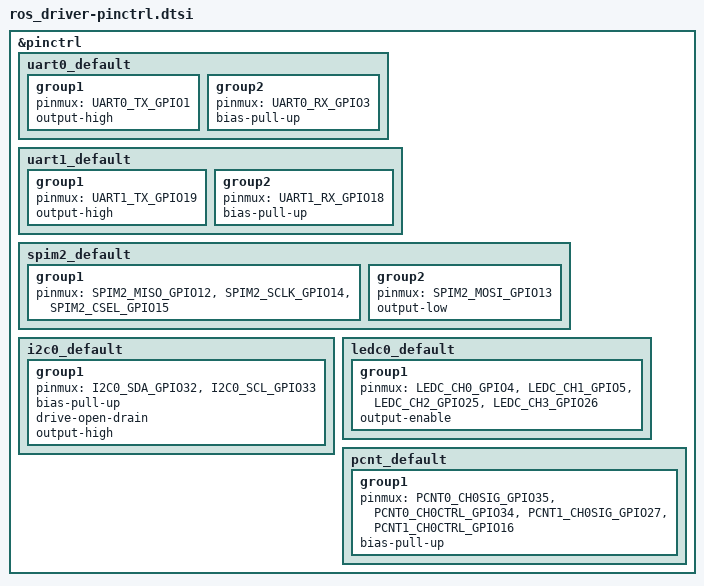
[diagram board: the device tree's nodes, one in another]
#include <zephyr/dt-bindings/pinctrl/esp-pinctrl-common.h>
#include <dt-bindings/pinctrl/esp32-pinctrl.h>
#include <zephyr/dt-bindings/pinctrl/esp32-gpio-sigmap.h>

&pinctrl {

	uart0_default: uart0_default {
		group1 {
			pinmux = <UART0_TX_GPIO1>;
			output-high;
		};
		group2 {
			pinmux = <UART0_RX_GPIO3>;
			bias-pull-up;
		};
	};

	uart1_default: uart1_default {
		group1 {
			pinmux = <UART1_TX_GPIO19>;
			output-high;
		};
		group2 {
			pinmux = <UART1_RX_GPIO18>;
			bias-pull-up;
		};
	};

	spim2_default: spim2_default {
		group1 {
			pinmux = <SPIM2_MISO_GPIO12>,
				 <SPIM2_SCLK_GPIO14>,
				 <SPIM2_CSEL_GPIO15>;
		};
		group2 {
			pinmux = <SPIM2_MOSI_GPIO13>;
			output-low;
		};
	};

	i2c0_default: i2c0_default {
		group1 {
			pinmux = <I2C0_SDA_GPIO32>,
				 <I2C0_SCL_GPIO33>;
			bias-pull-up;
			drive-open-drain;
			output-high;
		};
	};

	ledc0_default: ledc0_default {
		group1 {
			pinmux = <LEDC_CH0_GPIO4>,
				 <LEDC_CH1_GPIO5>,
				 <LEDC_CH2_GPIO25>,
				 <LEDC_CH3_GPIO26>;
			output-enable;
		};
	};

	pcnt_default: pcnt_default {
		group1 {
			pinmux = <PCNT0_CH0SIG_GPIO35>,
				 <PCNT0_CH0CTRL_GPIO34>,
				 <PCNT1_CH0SIG_GPIO27>,
				 <PCNT1_CH0CTRL_GPIO16>;
			bias-pull-up;
		};
	};
};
